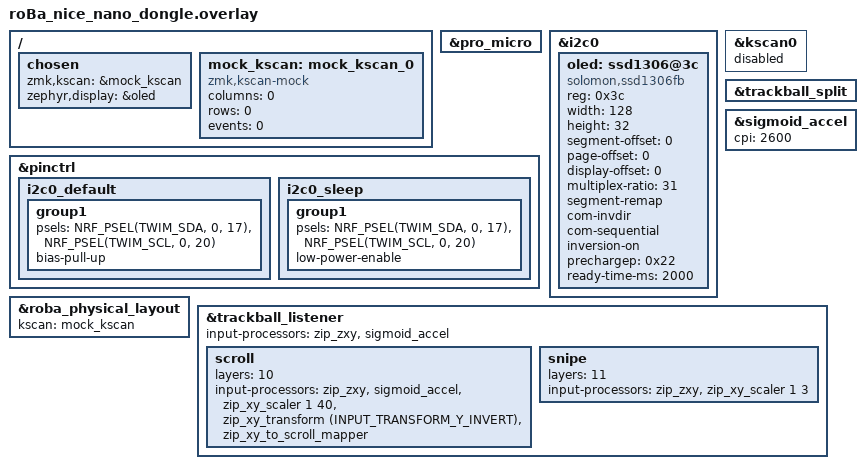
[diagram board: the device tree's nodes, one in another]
/* Alias xiao_d to pro_micro so roBa.dtsi resolves on nice_nano_v2.
 * All nodes that reference xiao_d (kscan0, encoders) are disabled below. */
xiao_d: &pro_micro {};

/* SSD1306 OLED on the default nice!nano v2 I2C0 bus (SDA=P0.17/D2, SCL=P0.20/D3).
 * Default I2C address 0x3c; change to 0x3d if your module has SA0 pulled high.
 * Change height to 64 for a 128x64 display (and multiplex-ratio to 63). */
&i2c0 {
    status = "okay";

    oled: ssd1306@3c {
        compatible = "solomon,ssd1306fb";
        reg = <0x3c>;
        width = <128>;
        height = <32>;
        segment-offset = <0>;
        page-offset = <0>;
        display-offset = <0>;
        multiplex-ratio = <31>;
        segment-remap;
        com-invdir;
        com-sequential;
        inversion-on;
        prechargep = <0x22>;
        ready-time-ms = <2000>;
    };
};

&pinctrl {
    i2c0_default: i2c0_default {
        group1 {
            psels = <NRF_PSEL(TWIM_SDA, 0, 17)>,
                    <NRF_PSEL(TWIM_SCL, 0, 20)>;
            bias-pull-up;
        };
    };
    i2c0_sleep: i2c0_sleep {
        group1 {
            psels = <NRF_PSEL(TWIM_SDA, 0, 17)>,
                    <NRF_PSEL(TWIM_SCL, 0, 20)>;
            low-power-enable;
        };
    };
};

#include "roBa.dtsi"
#include <input/processors/xyz.dtsi>
#include <behaviors/input_processor_sigmoid_accel.dtsi>

/ {
    chosen {
        zmk,kscan = &mock_kscan;
        zephyr,display = &oled;
    };

    mock_kscan: mock_kscan_0 {
        compatible = "zmk,kscan-mock";
        columns = <0>;
        rows = <0>;
        events = <0>;
    };
};

&kscan0 {
    status = "disabled";
};

&roba_physical_layout {
    kscan = <&mock_kscan>;
};

&trackball_split {
    status = "okay";
};

&sigmoid_accel {
    cpi = <2600>;
};

&trackball_listener {
    status = "okay";
    input-processors = <&zip_zxy>, <&sigmoid_accel>;

    scroll {
        layers = <10>;
        input-processors = <&zip_zxy>, <&sigmoid_accel>, <&zip_xy_scaler 1 40>, <&zip_xy_transform (INPUT_TRANSFORM_Y_INVERT)>, <&zip_xy_to_scroll_mapper>;
    };

    snipe {
        layers = <11>;
        input-processors = <&zip_zxy>, <&zip_xy_scaler 1 3>;
    };
};
